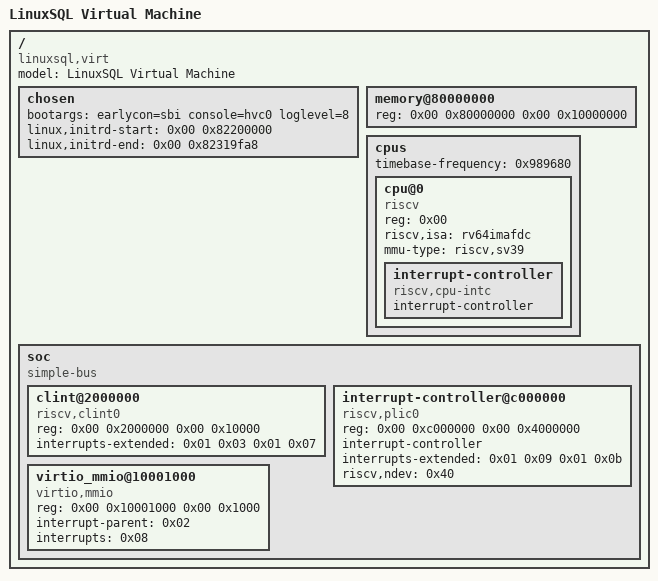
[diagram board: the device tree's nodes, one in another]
/dts-v1/;

/ {
    #address-cells = <0x02>;
    #size-cells = <0x02>;
    compatible = "linuxsql,virt";
    model = "LinuxSQL Virtual Machine";

    chosen {
        bootargs = "earlycon=sbi console=hvc0 loglevel=8";
        linux,initrd-start = <0x00 0x82200000>;
        linux,initrd-end = <0x00 0x82319fa8>;
    };

    memory@80000000 {
        device_type = "memory";
        reg = <0x00 0x80000000 0x00 0x10000000>;
    };

    cpus {
        #address-cells = <0x01>;
        #size-cells = <0x00>;
        timebase-frequency = <0x989680>;

        cpu@0 {
            device_type = "cpu";
            reg = <0x00>;
            compatible = "riscv";
            riscv,isa = "rv64imafdc";
            mmu-type = "riscv,sv39";
            status = "okay";

            interrupt-controller {
                #interrupt-cells = <0x01>;
                compatible = "riscv,cpu-intc";
                interrupt-controller;
                phandle = <0x01>;
            };
        };
    };

    soc {
        #address-cells = <0x02>;
        #size-cells = <0x02>;
        compatible = "simple-bus";
        ranges;

        clint@2000000 {
            compatible = "riscv,clint0";
            reg = <0x00 0x2000000 0x00 0x10000>;
            interrupts-extended = <0x01 0x03 0x01 0x07>;
        };

        interrupt-controller@c000000 {
            compatible = "riscv,plic0";
            reg = <0x00 0xc000000 0x00 0x4000000>;
            #interrupt-cells = <0x01>;
            interrupt-controller;
            interrupts-extended = <0x01 0x09 0x01 0x0b>;
            riscv,ndev = <0x40>;
            phandle = <0x02>;
        };

        virtio_mmio@10001000 {
            compatible = "virtio,mmio";
            reg = <0x00 0x10001000 0x00 0x1000>;
            interrupt-parent = <0x02>;
            interrupts = <0x08>;
        };
    };
};
